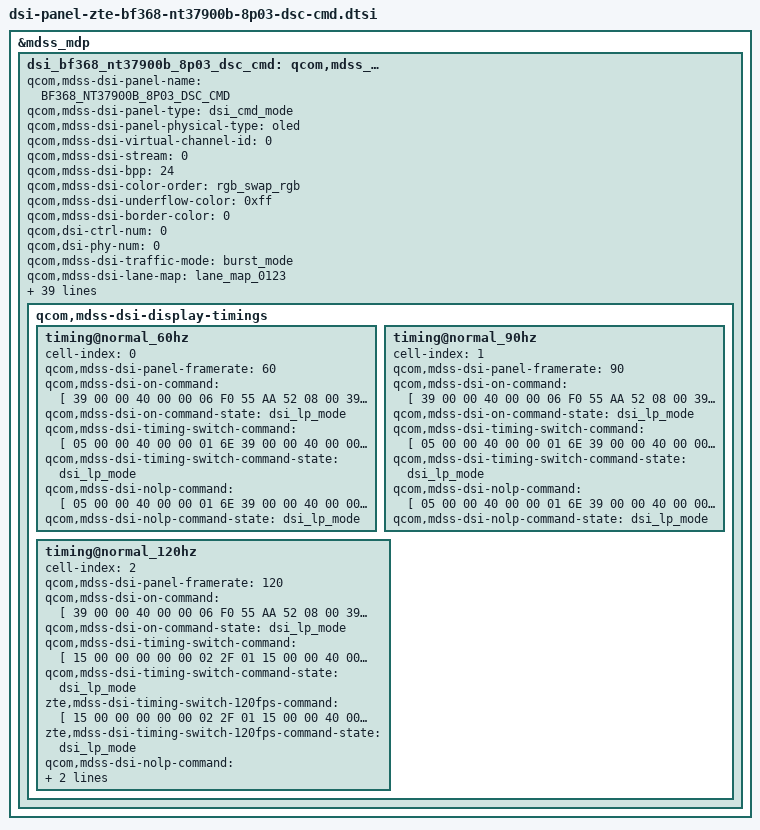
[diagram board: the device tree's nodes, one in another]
// SPDX-License-Identifier: BSD-3-Clause
/*
 * Copyright (c) 2023-2024 Qualcomm Innovation Center, Inc. All rights reserved.
 */

&mdss_mdp {
	dsi_bf368_nt37900b_8p03_dsc_cmd: qcom,mdss_dsi_bf368_nt37900b_8p03_dsc_cmd {
		qcom,mdss-dsi-panel-name =
				"BF368_NT37900B_8P03_DSC_CMD";
		qcom,mdss-dsi-panel-type = "dsi_cmd_mode";
		qcom,mdss-dsi-panel-physical-type = "oled";
		qcom,mdss-dsi-virtual-channel-id = <0>;
		qcom,mdss-dsi-stream = <0>;
		qcom,mdss-dsi-bpp = <24>;
		qcom,mdss-dsi-color-order = "rgb_swap_rgb";
		qcom,mdss-dsi-underflow-color = <0xff>;
		qcom,mdss-dsi-border-color = <0>;
		qcom,dsi-ctrl-num = <0>;
		qcom,dsi-phy-num = <0>;
		qcom,mdss-dsi-traffic-mode = "burst_mode";
		qcom,mdss-dsi-lane-map = "lane_map_0123";
		qcom,mdss-dsi-bllp-eof-power-mode;
		qcom,mdss-dsi-bllp-power-mode;
		qcom,mdss-dsi-lane-0-state;
		qcom,mdss-dsi-lane-1-state;
		qcom,mdss-dsi-lane-2-state;
		qcom,mdss-dsi-lane-3-state;
		qcom,mdss-dsi-lp11-init;
		qcom,mdss-dsi-tx-eot-append;
		qcom,mdss-dsi-dma-trigger = "trigger_sw";
		qcom,mdss-dsi-mdp-trigger = "none";
		qcom,mdss-dsi-reset-sequence = <1 10>, <0 10>, <1 40>;
		qcom,mdss-dsi-te-pin-select = <1>;
		qcom,mdss-dsi-te-dcs-command = <1>;
		qcom,mdss-dsi-te-check-enable;
		qcom,mdss-dsi-te-using-te-pin;
		qcom,mdss-dsi-bl-min-level = <1>;
		qcom,mdss-dsi-bl-max-level = <4095>;
		qcom,mdss-dsi-bl-pmic-control-type = "bl_ctrl_dcs";
		qcom,mdss-dsi-panel-hdr-enabled;
		qcom,mdss-dsi-panel-hdr-color-primaries = <14500 15500 34015
			15980 13030 34670 6950 2565>;
		qcom,mdss-dsi-panel-peak-brightness = <6680000>;
		qcom,mdss-dsi-panel-blackness-level = <20>;
		qcom,mdss-pan-physical-width-dimension = <72>;
		qcom,mdss-pan-physical-height-dimension = <158>;
		qcom,bl-dcs-cmd-state = "dsi_lp_mode";
		qcom,bl-dsc-cmd-state = "dsi_lp_mode";
		qcom,mdss-disable-cesta-hw-sleep;
		qcom,mdss-dsi-display-timings {
			timing@normal_60hz {
				cell-index = <0>;
				qcom,mdss-dsi-panel-framerate = <60>;
				#include "dsi-panel-zte-bf368-nt37900b-8p03-dsc-cmd-common.dtsi"
				qcom,mdss-dsi-on-command = [
					//Chopper modify
					39 00 00 40 00 00 06 F0 55 AA 52 08 00
					39 00 00 40 00 00 07 C8 0D 0D 0D 0D 08 08
					15 00 00 40 00 00 02 6F 0B
					39 00 00 40 00 00 09 C8 0C 0C 04 04 0C 0C 08 08
					39 00 00 40 00 00 06 F0 55 AA 52 08 01
					15 00 00 40 00 00 02 6F 03
					15 00 00 40 00 00 02 D9 40
					15 00 00 40 00 00 02 6F 23
					39 00 00 00 00 00 04 D9 C1 C9 12
					//fix panel flush
					39 00 00 40 00 00 06 F0 55 AA 52 08 00
					15 00 00 40 00 00 02 6F 1C
					39 00 00 40 00 00 05 B2 0F FF 0F FF
					15 00 00 40 00 00 02 6F CD
					39 00 00 40 00 00 05 B2 0F FF 0F FF
					15 00 00 40 00 00 02 6F D6
					15 00 00 00 00 00 02 B2 02
					//cmd3 page0
					39 00 00 40 00 00 05 FF AA 55 A5 80
					//OSC1 138.6Mhz OSC2 184.8Mhz
					15 00 00 40 00 00 02 6F 29
					39 00 00 40 00 00 03 F8 0E 36
					15 00 00 40 00 00 02 6F 0D
					39 00 00 00 00 00 03 F8 01 7F
					//cmd3 page1
					39 00 00 00 00 00 05 FF AA 55 A5 81
					//hclk_vbp not stop
					15 00 00 40 00 00 02 6F 02
					15 00 00 40 00 00 02 F9 04
					15 00 00 40 00 00 02 6F 0E
					15 00 00 00 00 00 02 F5 2B
					//ESD MIPI error keep RAM
					39 00 00 40 00 00 06 F0 55 AA 52 08 03
					39 00 00 40 00 00 04 C8 01 FF FB
					39 00 00 40 00 00 05 FF AA 55 A5 80
					15 00 00 40 00 00 02 6F 22
					15 00 00 00 00 00 02 FE 40
					//CMD3 Page2
					39 00 00 00 00 00 05 FF AA 55 A5 82
					//MIPI timing optimize
					15 00 00 40 00 00 02 6F 11
					15 00 00 00 00 00 02 F8 0F
					//CMD2 Disable
					39 00 00 40 00 00 06 F0 55 AA 52 00 00
					// CMD3 Disable
					39 00 00 00 00 00 05 FF AA 55 A5 00
					//Enable 360Hz TE Fix TE2 360
					15 00 00 40 00 00 02 6F 26
					39 00 00 40 00 00 08 44 02 98 02 98 68 03 00
					15 00 00 40 00 00 02 6F 4F
					39 00 00 40 00 00 03 44 00 00
					15 00 00 40 00 00 02 6F 63
					15 00 00 40 00 00 02 44 66
					15 00 00 40 00 00 02 6F 14
					15 00 00 40 00 00 02 35 60
					15 00 00 40 00 00 02 6F 04
					15 00 00 00 00 00 02 35 00
					//Fix Sync2 360hz
					15 00 00 40 00 00 02 6F 2D
					39 00 00 40 00 00 08 44 02 98 02 98 68 03 00
					15 00 00 40 00 00 02 6F 54
					39 00 00 40 00 00 03 44 00 00
					15 00 00 40 00 00 02 6F 63
					15 00 00 40 00 00 02 44 66
					15 00 00 40 00 00 02 6F 15
					15 00 00 00 00 00 02 35 E0
					//TE interrput
					15 00 00 40 00 00 02 6F 06
					15 00 00 00 00 00 02 6D 48
					//te on
					05 00 00 40 00 00 01 35
					15 00 00 40 00 00 02 53 20
					39 00 00 40 00 00 03 5F 00 00
					15 00 00 40 00 00 02 A2 01
					39 00 00 40 00 00 05 2A 00 00 09 AF
					39 00 00 40 00 00 05 2B 00 00 08 97
					39 00 00 40 00 00 03 90 03 43
					39 00 00 00 00 00 13 91 89 28 00 14 C2 00 03 6D 02 A7 00 11 05 0E 02 2F 10 D0
					//switch 120 fps
					//15 00 00 00 00 00 02 2F 01
					//brightness
					39 01 00 00 00 00 03 51 00 00
					05 01 00 00 64 00 01 11
					05 01 00 00 14 00 01 29
					// 60fps te1
					05 00 00 40 00 00 01 6E
					39 00 00 40 00 00 06 F0 55 AA 52 08 01
					15 00 00 40 00 00 02 6F E4
					39 00 00 40 00 00 09 E5 7F 7F 20 20 20 20 20 20
					39 00 00 40 00 00 06 F0 55 AA 52 08 00
					15 00 00 40 00 00 02 6F 21
					15 00 00 40 00 00 02 BA 00
					15 00 00 40 00 00 02 6F 25
					15 00 00 40 00 00 02 BA 00
					15 00 00 40 00 00 02 6F 31
					15 00 00 40 00 00 02 BA 09
					15 00 00 40 00 00 02 6F 41
					15 00 00 40 00 00 02 BA 21
					15 00 00 40 00 00 02 6F 45
					15 00 00 40 00 00 02 BA 21
					15 00 00 40 00 00 02 6F 51
					15 00 00 40 00 00 02 BA 00
					15 00 00 40 00 00 02 6F 55
					15 00 00 40 00 00 02 BA 00
					15 00 00 40 00 00 02 6F 6C
					15 00 00 40 00 00 02 BA 00
					15 00 00 40 00 00 02 6F 75
					15 00 00 40 00 00 02 BA 03 //60fps
					15 00 00 40 00 00 02 6F A5
					15 00 00 40 00 00 02 BA 01
					15 00 00 40 00 00 02 6F A9
					15 00 00 40 00 00 02 BA 00
					15 00 00 40 00 00 02 6F AD
					15 00 00 40 00 00 02 BA 00
					15 00 00 40 00 00 02 6F B1
					15 00 00 40 00 00 02 BA 00
					15 00 00 40 00 00 02 2F 30
					15 00 00 40 00 00 02 6D 81
					39 00 00 40 00 00 06 F0 55 AA 52 08 01
					15 00 00 40 00 00 02 6F 67
					39 00 00 40 00 00 05 B9 00 65 66 66
					15 00 00 40 00 00 02 6F 6F
					39 00 00 00 00 00 05 B9 00 43 44 44
					//te1 60 te2 60
					15 00 00 40 00 00 02 6F 26
					39 00 00 40 00 00 08 44 11 98 11 98 68 12 00
					15 00 00 40 00 00 02 6F 4F
					39 00 00 40 00 00 03 44 00 00
					15 00 00 40 00 00 02 6F 63
					15 00 00 40 00 00 02 44 66
					15 00 00 40 00 00 02 6F 14
					15 00 00 40 00 00 02 35 60
					15 00 00 40 00 00 02 6F 04
					15 00 00 40 00 00 02 35 00
					39 00 00 40 00 00 06 F0 55 AA 52 08 00
					39 00 00 00 00 00 03 BE 47 54
					];
				qcom,mdss-dsi-on-command-state = "dsi_lp_mode";
				qcom,mdss-dsi-timing-switch-command = [
					// 60fps te1
					05 00 00 40 00 00 01 6E
					39 00 00 40 00 00 06 F0 55 AA 52 08 01
					15 00 00 40 00 00 02 6F E4
					39 00 00 40 00 00 09 E5 7F 7F 20 20 20 20 20 20
					39 00 00 40 00 00 06 F0 55 AA 52 08 00
					15 00 00 40 00 00 02 6F 21
					15 00 00 40 00 00 02 BA 00
					15 00 00 40 00 00 02 6F 25
					15 00 00 40 00 00 02 BA 00
					15 00 00 40 00 00 02 6F 31
					15 00 00 40 00 00 02 BA 09
					15 00 00 40 00 00 02 6F 41
					15 00 00 40 00 00 02 BA 21
					15 00 00 40 00 00 02 6F 45
					15 00 00 40 00 00 02 BA 21
					15 00 00 40 00 00 02 6F 51
					15 00 00 40 00 00 02 BA 00
					15 00 00 40 00 00 02 6F 55
					15 00 00 40 00 00 02 BA 00
					15 00 00 40 00 00 02 6F 6C
					15 00 00 40 00 00 02 BA 00
					15 00 00 40 00 00 02 6F 75
					15 00 00 40 00 00 02 BA 03 //60fps
					15 00 00 40 00 00 02 6F A5
					15 00 00 40 00 00 02 BA 01
					15 00 00 40 00 00 02 6F A9
					15 00 00 40 00 00 02 BA 00
					15 00 00 40 00 00 02 6F AD
					15 00 00 40 00 00 02 BA 00
					15 00 00 40 00 00 02 6F B1
					15 00 00 40 00 00 02 BA 00
					15 00 00 40 00 00 02 2F 30
					15 00 00 40 00 00 02 6D 81
					39 00 00 40 00 00 06 F0 55 AA 52 08 01
					15 00 00 40 00 00 02 6F 67
					39 00 00 40 00 00 05 B9 00 65 66 66
					15 00 00 40 00 00 02 6F 6F
					39 00 00 40 00 00 05 B9 00 43 44 44
					//te1 60 te2 60
					15 00 00 40 00 00 02 6F 26
					39 00 00 40 00 00 08 44 11 98 11 98 68 12 00
					15 00 00 40 00 00 02 6F 4F
					39 00 00 40 00 00 03 44 00 00
					15 00 00 40 00 00 02 6F 63
					15 00 00 40 00 00 02 44 66
					15 00 00 40 00 00 02 6F 14
					15 00 00 40 00 00 02 35 60
					15 00 00 40 00 00 02 6F 04
					15 00 00 40 00 00 02 35 00
					39 00 00 40 00 00 06 F0 55 AA 52 08 00
					39 00 00 00 00 00 03 BE 47 54
					];
				qcom,mdss-dsi-timing-switch-command-state = "dsi_lp_mode";
				qcom,mdss-dsi-nolp-command = [
					05 00 00 40 00 00 01 6E
					39 00 00 40 00 00 06 F0 55 AA 52 08 01
					15 00 00 40 00 00 02 6F E4
					39 00 00 40 00 00 09 E5 7F 7F 20 20 20 20 20 20
					39 00 00 40 00 00 06 F0 55 AA 52 08 00
					15 00 00 40 00 00 02 6F 21
					15 00 00 40 00 00 02 BA 00
					15 00 00 40 00 00 02 6F 25
					15 00 00 40 00 00 02 BA 00
					15 00 00 40 00 00 02 6F 31
					15 00 00 40 00 00 02 BA 09
					15 00 00 40 00 00 02 6F 41
					15 00 00 40 00 00 02 BA 21
					15 00 00 40 00 00 02 6F 45
					15 00 00 40 00 00 02 BA 21
					15 00 00 40 00 00 02 6F 51
					15 00 00 40 00 00 02 BA 00
					15 00 00 40 00 00 02 6F 55
					15 00 00 40 00 00 02 BA 00
					15 00 00 40 00 00 02 6F 6C
					15 00 00 40 00 00 02 BA 00
					15 00 00 40 00 00 02 6F 75
					15 00 00 40 00 00 02 BA 03 //60fps
					15 00 00 40 00 00 02 6F A5
					15 00 00 40 00 00 02 BA 01
					15 00 00 40 00 00 02 6F A9
					15 00 00 40 00 00 02 BA 00
					15 00 00 40 00 00 02 6F AD
					15 00 00 40 00 00 02 BA 00
					15 00 00 40 00 00 02 6F B1
					15 00 00 40 00 00 02 BA 00
					15 00 00 40 00 00 02 2F 30
					15 00 00 40 00 00 02 6D 81
					39 00 00 40 00 00 06 F0 55 AA 52 08 01
					15 00 00 40 00 00 02 6F 67
					39 00 00 40 00 00 05 B9 00 65 66 66
					15 00 00 40 00 00 02 6F 6F
					39 00 00 40 00 00 05 B9 00 43 44 44
					//te1 60 te2 60
					15 00 00 40 00 00 02 6F 26
					39 00 00 40 00 00 08 44 11 98 11 98 68 12 00
					15 00 00 40 00 00 02 6F 4F
					39 00 00 40 00 00 03 44 00 00
					15 00 00 40 00 00 02 6F 63
					15 00 00 40 00 00 02 44 66
					15 00 00 40 00 00 02 6F 14
					15 00 00 40 00 00 02 35 60
					15 00 00 40 00 00 02 6F 04
					15 00 00 40 00 00 02 35 00
					39 00 00 40 00 00 06 F0 55 AA 52 08 00
					39 00 00 00 00 00 03 BE 47 54
					];
				qcom,mdss-dsi-nolp-command-state =
					"dsi_lp_mode";
			};
			timing@normal_90hz {
				cell-index = <1>;
				qcom,mdss-dsi-panel-framerate = <90>;
				#include "dsi-panel-zte-bf368-nt37900b-8p03-dsc-cmd-common.dtsi"
				qcom,mdss-dsi-on-command = [
					//Chopper modify
					39 00 00 40 00 00 06 F0 55 AA 52 08 00
					39 00 00 40 00 00 07 C8 0D 0D 0D 0D 08 08
					15 00 00 40 00 00 02 6F 0B
					39 00 00 40 00 00 09 C8 0C 0C 04 04 0C 0C 08 08
					39 00 00 40 00 00 06 F0 55 AA 52 08 01
					15 00 00 40 00 00 02 6F 03
					15 00 00 40 00 00 02 D9 40
					15 00 00 40 00 00 02 6F 23
					39 00 00 00 00 00 04 D9 C1 C9 12
					//fix panel flush
					39 00 00 40 00 00 06 F0 55 AA 52 08 00
					15 00 00 40 00 00 02 6F 1C
					39 00 00 40 00 00 05 B2 0F FF 0F FF
					15 00 00 40 00 00 02 6F CD
					39 00 00 40 00 00 05 B2 0F FF 0F FF
					15 00 00 40 00 00 02 6F D6
					15 00 00 00 00 00 02 B2 02
					//cmd3 page0
					39 00 00 40 00 00 05 FF AA 55 A5 80
					//OSC1 138.6Mhz OSC2 184.8Mhz
					15 00 00 40 00 00 02 6F 29
					39 00 00 40 00 00 03 F8 0E 36
					15 00 00 40 00 00 02 6F 0D
					39 00 00 00 00 00 03 F8 01 7F
					//cmd3 page1
					39 00 00 00 00 00 05 FF AA 55 A5 81
					//hclk_vbp not stop
					15 00 00 40 00 00 02 6F 02
					15 00 00 40 00 00 02 F9 04
					15 00 00 40 00 00 02 6F 0E
					15 00 00 00 00 00 02 F5 2B
					//ESD MIPI error keep RAM
					39 00 00 40 00 00 06 F0 55 AA 52 08 03
					39 00 00 40 00 00 04 C8 01 FF FB
					39 00 00 40 00 00 05 FF AA 55 A5 80
					15 00 00 40 00 00 02 6F 22
					15 00 00 00 00 00 02 FE 40
					//CMD3 Page2
					39 00 00 00 00 00 05 FF AA 55 A5 82
					//MIPI timing optimize
					15 00 00 40 00 00 02 6F 11
					15 00 00 00 00 00 02 F8 0F
					//CMD2 Disable
					39 00 00 40 00 00 06 F0 55 AA 52 00 00
					// CMD3 Disable
					39 00 00 00 00 00 05 FF AA 55 A5 00
					//Enable 360Hz TE Fix TE2 360
					15 00 00 40 00 00 02 6F 26
					39 00 00 40 00 00 08 44 02 98 02 98 68 03 00
					15 00 00 40 00 00 02 6F 4F
					39 00 00 40 00 00 03 44 00 00
					15 00 00 40 00 00 02 6F 63
					15 00 00 40 00 00 02 44 66
					15 00 00 40 00 00 02 6F 14
					15 00 00 40 00 00 02 35 60
					15 00 00 40 00 00 02 6F 04
					15 00 00 00 00 00 02 35 00
					//Fix Sync2 360hz
					15 00 00 40 00 00 02 6F 2D
					39 00 00 40 00 00 08 44 02 98 02 98 68 03 00
					15 00 00 40 00 00 02 6F 54
					39 00 00 40 00 00 03 44 00 00
					15 00 00 40 00 00 02 6F 63
					15 00 00 40 00 00 02 44 66
					15 00 00 40 00 00 02 6F 15
					15 00 00 00 00 00 02 35 E0
					//TE interrput
					15 00 00 40 00 00 02 6F 06
					15 00 00 00 00 00 02 6D 48
					//te on
					05 00 00 40 00 00 01 35
					15 00 00 40 00 00 02 53 20
					39 00 00 40 00 00 03 5F 00 00
					15 00 00 40 00 00 02 A2 01
					39 00 00 40 00 00 05 2A 00 00 09 AF
					39 00 00 40 00 00 05 2B 00 00 08 97
					39 00 00 40 00 00 03 90 03 43
					39 00 00 00 00 00 13 91 89 28 00 14 C2 00 03 6D 02 A7 00 11 05 0E 02 2F 10 D0
					//switch 120 fps
					//15 00 00 00 00 00 02 2F 01
					//brightness
					39 01 00 00 00 00 03 51 00 00
					05 01 00 00 64 00 01 11
					05 01 00 00 14 00 01 29
					// 90fps te1
					05 01 00 40 00 00 01 6E
					39 01 00 40 00 00 06 F0 55 AA 52 08 01
					15 01 00 40 00 00 02 6F E4
					39 01 00 40 00 00 09 E5 7F 7F 20 20 20 20 20 20
					39 01 00 40 00 00 06 F0 55 AA 52 08 00
					15 01 00 40 00 00 02 6F 21
					15 01 00 40 00 00 02 BA 00
					15 01 00 40 00 00 02 6F 25
					15 01 00 40 00 00 02 BA 00
					15 01 00 40 00 00 02 6F 31
					15 01 00 40 00 00 02 BA 09
					15 01 00 40 00 00 02 6F 41
					15 01 00 40 00 00 02 BA 21
					15 01 00 40 00 00 02 6F 45
					15 01 00 40 00 00 02 BA 21
					15 01 00 40 00 00 02 6F 51
					15 01 00 40 00 00 02 BA 00
					15 01 00 40 00 00 02 6F 55
					15 01 00 40 00 00 02 BA 00
					15 01 00 40 00 00 02 6F 6C
					15 01 00 40 00 00 02 BA 00
					15 01 00 40 00 00 02 6F 75
					15 01 00 40 00 00 02 BA 01 //90fps
					15 01 00 40 00 00 02 6F A5
					15 01 00 40 00 00 02 BA 01
					15 01 00 40 00 00 02 6F A9
					15 01 00 40 00 00 02 BA 00
					15 01 00 40 00 00 02 6F AD
					15 01 00 40 00 00 02 BA 00
					15 01 00 40 00 00 02 6F B1
					15 01 00 40 00 00 02 BA 00
					15 01 00 40 00 00 02 2F 30
					15 01 00 40 00 00 02 6D 81
					39 01 00 40 00 00 06 F0 55 AA 52 08 01
					15 01 00 40 00 00 02 6F 67
					39 01 00 40 00 00 05 B9 00 65 66 66
					15 01 00 40 00 00 02 6F 6F
					39 01 00 00 00 00 05 B9 00 43 44 44
					//fix te2 90
					15 00 00 40 00 00 02 6F 26
					39 00 00 40 00 00 08 44 0B 98 0B 98 68 0C 00
					15 00 00 40 00 00 02 6F 4F
					39 00 00 40 00 00 03 44 00 00
					15 00 00 40 00 00 02 6F 63
					15 00 00 40 00 00 02 44 66
					15 00 00 40 00 00 02 6F 14
					15 00 00 40 00 00 02 35 60
					15 00 00 40 00 00 02 6F 04
					15 00 00 40 00 00 02 35 00
					39 00 00 40 00 00 06 F0 55 AA 52 08 00
					39 00 00 00 00 00 03 BE 47 54
					];
				qcom,mdss-dsi-on-command-state = "dsi_lp_mode";
				qcom,mdss-dsi-timing-switch-command = [
					// 90fps te1
					05 00 00 40 00 00 01 6E
					39 00 00 40 00 00 06 F0 55 AA 52 08 01
					15 00 00 40 00 00 02 6F E4
					39 00 00 40 00 00 09 E5 7F 7F 20 20 20 20 20 20
					39 00 00 40 00 00 06 F0 55 AA 52 08 00
					15 00 00 40 00 00 02 6F 21
					15 00 00 40 00 00 02 BA 00
					15 00 00 40 00 00 02 6F 25
					15 00 00 40 00 00 02 BA 00
					15 00 00 40 00 00 02 6F 31
					15 00 00 40 00 00 02 BA 09
					15 00 00 40 00 00 02 6F 41
					15 00 00 40 00 00 02 BA 21
					15 00 00 40 00 00 02 6F 45
					15 00 00 40 00 00 02 BA 21
					15 00 00 40 00 00 02 6F 51
					15 00 00 40 00 00 02 BA 00
					15 00 00 40 00 00 02 6F 55
					15 00 00 40 00 00 02 BA 00
					15 00 00 40 00 00 02 6F 6C
					15 00 00 40 00 00 02 BA 00
					15 00 00 40 00 00 02 6F 75
					15 00 00 40 00 00 02 BA 01 //90fps
					15 00 00 40 00 00 02 6F A5
					15 00 00 40 00 00 02 BA 01
					15 00 00 40 00 00 02 6F A9
					15 00 00 40 00 00 02 BA 00
					15 00 00 40 00 00 02 6F AD
					15 00 00 40 00 00 02 BA 00
					15 00 00 40 00 00 02 6F B1
					15 00 00 40 00 00 02 BA 00
					15 00 00 40 00 00 02 2F 30
					15 00 00 40 00 00 02 6D 81
					39 00 00 40 00 00 06 F0 55 AA 52 08 01
					15 00 00 40 00 00 02 6F 67
					39 00 00 40 00 00 05 B9 00 65 66 66
					15 00 00 40 00 00 02 6F 6F
					39 00 00 00 00 00 05 B9 00 43 44 44
					//fix te2 90
					15 00 00 40 00 00 02 6F 26
					39 00 00 40 00 00 08 44 0B 98 0B 98 68 0C 00
					15 00 00 40 00 00 02 6F 4F
					39 00 00 40 00 00 03 44 00 00
					15 00 00 40 00 00 02 6F 63
					15 00 00 40 00 00 02 44 66
					15 00 00 40 00 00 02 6F 14
					15 00 00 40 00 00 02 35 60
					15 00 00 40 00 00 02 6F 04
					15 00 00 40 00 00 02 35 00
					39 00 00 40 00 00 06 F0 55 AA 52 08 00
					39 00 00 00 00 00 03 BE 47 54
					];
				qcom,mdss-dsi-timing-switch-command-state = "dsi_lp_mode";
				qcom,mdss-dsi-nolp-command = [
					// 90fps te1
					05 00 00 40 00 00 01 6E
					39 00 00 40 00 00 06 F0 55 AA 52 08 01
					15 00 00 40 00 00 02 6F E4
					39 00 00 40 00 00 09 E5 7F 7F 20 20 20 20 20 20
					39 00 00 40 00 00 06 F0 55 AA 52 08 00
					15 00 00 40 00 00 02 6F 21
					15 00 00 40 00 00 02 BA 00
					15 00 00 40 00 00 02 6F 25
					15 00 00 40 00 00 02 BA 00
					15 00 00 40 00 00 02 6F 31
					15 00 00 40 00 00 02 BA 09
					15 00 00 40 00 00 02 6F 41
					15 00 00 40 00 00 02 BA 21
					15 00 00 40 00 00 02 6F 45
					15 00 00 40 00 00 02 BA 21
					15 00 00 40 00 00 02 6F 51
					15 00 00 40 00 00 02 BA 00
					15 00 00 40 00 00 02 6F 55
					15 00 00 40 00 00 02 BA 00
					15 00 00 40 00 00 02 6F 6C
					15 00 00 40 00 00 02 BA 00
					15 00 00 40 00 00 02 6F 75
					15 00 00 40 00 00 02 BA 01 //90fps
					15 00 00 40 00 00 02 6F A5
					15 00 00 40 00 00 02 BA 01
					15 00 00 40 00 00 02 6F A9
					15 00 00 40 00 00 02 BA 00
					15 00 00 40 00 00 02 6F AD
					15 00 00 40 00 00 02 BA 00
					15 00 00 40 00 00 02 6F B1
					15 00 00 40 00 00 02 BA 00
					15 00 00 40 00 00 02 2F 30
					15 00 00 40 00 00 02 6D 81
					39 00 00 40 00 00 06 F0 55 AA 52 08 01
					15 00 00 40 00 00 02 6F 67
					39 00 00 40 00 00 05 B9 00 65 66 66
					15 00 00 40 00 00 02 6F 6F
					39 00 00 00 00 00 05 B9 00 43 44 44
					//fix te2 90
					15 00 00 40 00 00 02 6F 26
					39 00 00 40 00 00 08 44 0B 98 0B 98 68 0C 00
					15 00 00 40 00 00 02 6F 4F
					39 00 00 40 00 00 03 44 00 00
					15 00 00 40 00 00 02 6F 63
					15 00 00 40 00 00 02 44 66
					15 00 00 40 00 00 02 6F 14
					15 00 00 40 00 00 02 35 60
					15 00 00 40 00 00 02 6F 04
					15 00 00 40 00 00 02 35 00
					39 00 00 40 00 00 06 F0 55 AA 52 08 00
					39 00 00 00 00 00 03 BE 47 54
					];
				qcom,mdss-dsi-nolp-command-state =
					"dsi_lp_mode";
			};
			timing@normal_120hz {
				cell-index = <2>;
				qcom,mdss-dsi-panel-framerate = <120>;
				#include "dsi-panel-zte-bf368-nt37900b-8p03-dsc-cmd-common.dtsi"
				qcom,mdss-dsi-on-command = [
					//Chopper modify
					39 00 00 40 00 00 06 F0 55 AA 52 08 00
					39 00 00 40 00 00 07 C8 0D 0D 0D 0D 08 08
					15 00 00 40 00 00 02 6F 0B
					39 00 00 40 00 00 09 C8 0C 0C 04 04 0C 0C 08 08
					39 00 00 40 00 00 06 F0 55 AA 52 08 01
					15 00 00 40 00 00 02 6F 03
					15 00 00 40 00 00 02 D9 40
					15 00 00 40 00 00 02 6F 23
					39 00 00 00 00 00 04 D9 C1 C9 12
					//fix panel flush
					39 00 00 40 00 00 06 F0 55 AA 52 08 00
					15 00 00 40 00 00 02 6F 1C
					39 00 00 40 00 00 05 B2 0F FF 0F FF
					15 00 00 40 00 00 02 6F CD
					39 00 00 40 00 00 05 B2 0F FF 0F FF
					15 00 00 40 00 00 02 6F D6
					15 00 00 00 00 00 02 B2 02
					//cmd3 page0
					39 00 00 40 00 00 05 FF AA 55 A5 80
					//OSC1 138.6Mhz OSC2 184.8Mhz
					15 00 00 40 00 00 02 6F 29
					39 00 00 40 00 00 03 F8 0E 36
					15 00 00 40 00 00 02 6F 0D
					39 00 00 00 00 00 03 F8 01 7F
					//cmd3 page1
					39 00 00 00 00 00 05 FF AA 55 A5 81
					//hclk_vbp not stop
					15 00 00 40 00 00 02 6F 02
					15 00 00 40 00 00 02 F9 04
					15 00 00 40 00 00 02 6F 0E
					15 00 00 00 00 00 02 F5 2B
					//ESD MIPI error keep RAM
					39 00 00 40 00 00 06 F0 55 AA 52 08 03
					39 00 00 40 00 00 04 C8 01 FF FB
					39 00 00 40 00 00 05 FF AA 55 A5 80
					15 00 00 40 00 00 02 6F 22
					15 00 00 00 00 00 02 FE 40
					//CMD3 Page2
					39 00 00 00 00 00 05 FF AA 55 A5 82
					//MIPI timing optimize
					15 00 00 40 00 00 02 6F 11
					15 00 00 00 00 00 02 F8 0F
					//CMD2 Disable
					39 00 00 40 00 00 06 F0 55 AA 52 00 00
					// CMD3 Disable
					39 00 00 00 00 00 05 FF AA 55 A5 00
					//Enable 360Hz TE Fix TE2 360
					15 00 00 40 00 00 02 6F 26
					39 00 00 40 00 00 08 44 02 98 02 98 68 03 00
					15 00 00 40 00 00 02 6F 4F
					39 00 00 40 00 00 03 44 00 00
					15 00 00 40 00 00 02 6F 63
					15 00 00 40 00 00 02 44 66
					15 00 00 40 00 00 02 6F 14
					15 00 00 40 00 00 02 35 60
					15 00 00 40 00 00 02 6F 04
					15 00 00 00 00 00 02 35 00
					//Fix Sync2 360hz
					15 00 00 40 00 00 02 6F 2D
					39 00 00 40 00 00 08 44 02 98 02 98 68 03 00
					15 00 00 40 00 00 02 6F 54
					39 00 00 40 00 00 03 44 00 00
					15 00 00 40 00 00 02 6F 63
					15 00 00 40 00 00 02 44 66
					15 00 00 40 00 00 02 6F 15
					15 00 00 00 00 00 02 35 E0
					//TE interrput
					15 00 00 40 00 00 02 6F 06
					15 00 00 00 00 00 02 6D 48
					//te on
					05 00 00 40 00 00 01 35
					15 00 00 40 00 00 02 53 20
					39 00 00 40 00 00 03 5F 00 00
					15 00 00 40 00 00 02 A2 01
					39 00 00 40 00 00 05 2A 00 00 09 AF
					39 00 00 40 00 00 05 2B 00 00 08 97
					39 00 00 40 00 00 03 90 03 43
					39 00 00 00 00 00 13 91 89 28 00 14 C2 00 03 6D 02 A7 00 11 05 0E 02 2F 10 D0
					//switch 120 fps
					15 00 00 00 00 00 02 2F 01
					//brightness
					39 01 00 00 00 00 03 51 00 00
					05 01 00 00 64 00 01 11
					05 01 00 00 14 00 01 29
					// te2 fix 120hz
					15 00 00 40 00 00 02 6F 26
					39 00 00 40 00 00 08 44 08 98 08 98 68 09 00
					15 00 00 40 00 00 02 6F 4F
					39 00 00 40 00 00 03 44 00 00
					15 00 00 40 00 00 02 6F 63
					15 00 00 40 00 00 02 44 66
					15 00 00 40 00 00 02 6F 14
					15 00 00 40 00 00 02 35 60
					15 00 00 40 00 00 02 6F 04
					15 00 00 40 00 00 02 35 00
					// te1 120 te2 120
					39 00 00 00 00 00 06 F0 55 AA 52 08 00
					39 00 00 00 00 00 03 BE 47 54
					];
				qcom,mdss-dsi-on-command-state = "dsi_lp_mode";
				qcom,mdss-dsi-timing-switch-command = [
					// te2 fix 120hz
					15 00 00 00 00 00 02 2F 01
					// te2 fix 120hz
					15 00 00 40 00 00 02 6F 26
					39 00 00 40 00 00 08 44 08 98 08 98 68 09 00
					15 00 00 40 00 00 02 6F 4F
					39 00 00 40 00 00 03 44 00 00
					15 00 00 40 00 00 02 6F 63
					15 00 00 40 00 00 02 44 66
					15 00 00 40 00 00 02 6F 14
					15 00 00 40 00 00 02 35 60
					15 00 00 40 00 00 02 6F 04
					15 00 00 40 00 00 02 35 00
					// te1 120 te2 120
					39 00 00 00 00 00 06 F0 55 AA 52 08 00
					39 00 00 00 00 00 03 BE 47 54
					];
				qcom,mdss-dsi-timing-switch-command-state = "dsi_lp_mode";
				zte,mdss-dsi-timing-switch-120fps-command = [
					// te2 fix 120hz
					15 00 00 00 00 00 02 2F 01
					// te2 fix 120hz
					15 00 00 40 00 00 02 6F 26
					39 00 00 40 00 00 08 44 08 98 08 98 68 09 00
					15 00 00 40 00 00 02 6F 4F
					39 00 00 40 00 00 03 44 00 00
					15 00 00 40 00 00 02 6F 63
					15 00 00 40 00 00 02 44 66
					15 00 00 40 00 00 02 6F 14
					15 00 00 40 00 00 02 35 60
					15 00 00 40 00 00 02 6F 04
					15 00 00 40 00 00 02 35 00
					// te1 120 te2 120
					39 00 00 00 00 00 06 F0 55 AA 52 08 00
					39 00 00 00 00 00 03 BE 47 54
				];
				zte,mdss-dsi-timing-switch-120fps-command-state = "dsi_lp_mode";
				qcom,mdss-dsi-nolp-command = [
					// te2 fix 120hz
					15 00 00 00 00 00 02 2F 01
					// te2 fix 120hz
					15 00 00 40 00 00 02 6F 26
					39 00 00 40 00 00 08 44 08 98 08 98 68 09 00
					15 00 00 40 00 00 02 6F 4F
					39 00 00 40 00 00 03 44 00 00
					15 00 00 40 00 00 02 6F 63
					15 00 00 40 00 00 02 44 66
					15 00 00 40 00 00 02 6F 14
					15 00 00 40 00 00 02 35 60
					15 00 00 40 00 00 02 6F 04
					15 00 00 40 00 00 02 35 00
					// te1 120 te2 120
					39 00 00 00 00 00 06 F0 55 AA 52 08 00
					39 00 00 00 00 00 03 BE 47 54
					];
				qcom,mdss-dsi-nolp-command-state =
					"dsi_lp_mode";
			};
		};
	};
};

/* zte dsip power supply */
&dsi_bf368_nt37900b_8p03_dsc_cmd {
	qcom,panel-supply-entries = <&dsi_panel_pri_pwr_supply>;
	qcom,mdss-dsi-bl-pmic-control-type = "bl_ctrl_dcs";
	qcom,mdss-brightness-max-level = <4095>;
	qcom,mdss-dsi-bl-inverted-dbv;
	qcom,platform-reset-gpio = <&tlmm 98 0>;
	qcom,ulps-enabled;
	qcom,dsi-select-clocks = "pll_byte_clk0", "pll_dsi_clk0";
};

/* zte define */
&dsi_bf368_nt37900b_8p03_dsc_cmd {
	zte,min-fps-index1 = <20>;
	zte,min-fps-index2 = <22>;
};
